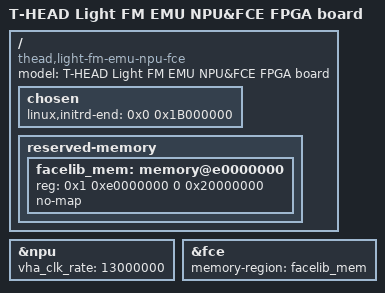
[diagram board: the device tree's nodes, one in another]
/* SPDX-License-Identifier: GPL-2.0 */
/*
 * Copyright (C) 2021 Alibaba Group Holding Limited.
 */

#include "light-fm-emu.dts"

/ {
	model = "T-HEAD Light FM EMU NPU&FCE FPGA board";
	compatible = "thead,light-fm-emu-npu-fce", "thead,light";

	chosen {
		linux,initrd-end = <0x0 0x1B000000>;
	};

	reserved-memory {
		#address-cells = <2>;
		#size-cells = <2>;
		ranges;

		facelib_mem: memory@e0000000 {
			reg = <0x1 0xe0000000 0 0x20000000>;
			no-map;
		};
	};
};

&npu {
	vha_clk_rate = <13000000>;
	status = "okay";
};

&fce {
	memory-region = <&facelib_mem>;
	status = "okay";
};

